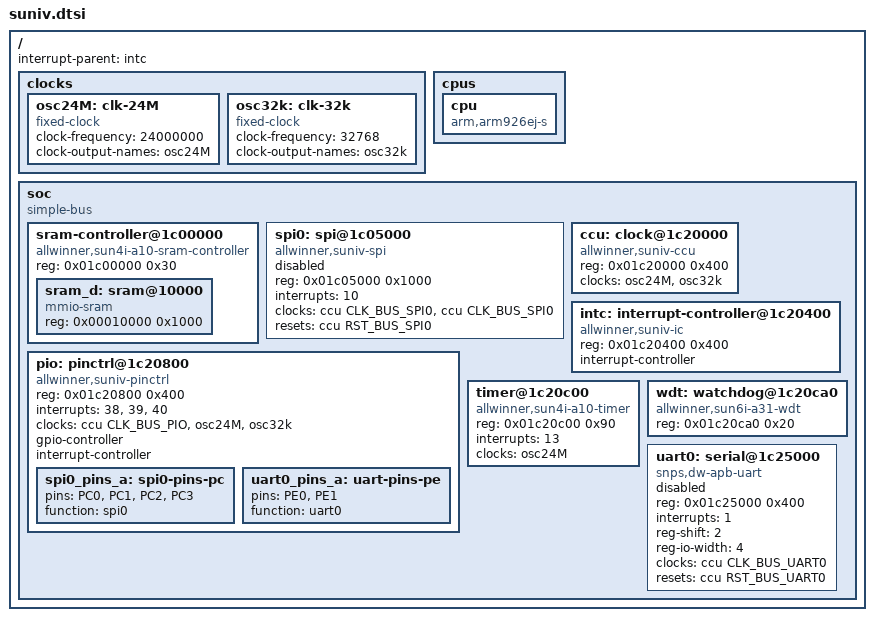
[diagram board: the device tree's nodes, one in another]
// SPDX-License-Identifier: (GPL-2.0+ OR X11)
/*
 * Copyright 2018 Icenowy Zheng <icenowy@aosc.io>
 */

#include <dt-bindings/clock/suniv-ccu.h>
#include <dt-bindings/reset/suniv-ccu.h>

/ {
	#address-cells = <1>;
	#size-cells = <1>;
	interrupt-parent = <&intc>;

	clocks {
		#address-cells = <1>;
		#size-cells = <1>;
		ranges;

		osc24M: clk-24M {
			#clock-cells = <0>;
			compatible = "fixed-clock";
			clock-frequency = <24000000>;
			clock-output-names = "osc24M";
		};

		osc32k: clk-32k {
			#clock-cells = <0>;
			compatible = "fixed-clock";
			clock-frequency = <32768>;
			clock-output-names = "osc32k";
		};
	};

	cpus {
		#address-cells = <0>;
		#size-cells = <0>;

		cpu {
			compatible = "arm,arm926ej-s";
			device_type = "cpu";
		};
	};

	soc {
		compatible = "simple-bus";
		#address-cells = <1>;
		#size-cells = <1>;
		ranges;

		sram-controller@1c00000 {
			compatible = "allwinner,sun4i-a10-sram-controller";
			reg = <0x01c00000 0x30>;
			#address-cells = <1>;
			#size-cells = <1>;
			ranges;

			sram_d: sram@10000 {
				compatible = "mmio-sram";
				reg = <0x00010000 0x1000>;
				#address-cells = <1>;
				#size-cells = <1>;
				ranges = <0 0x00010000 0x1000>;
			};
		};

		spi0: spi@1c05000 {
			compatible = "allwinner,suniv-spi",
				     "allwinner,sun8i-h3-spi";
			reg = <0x01c05000 0x1000>;
			interrupts = <10>;
			clocks = <&ccu CLK_BUS_SPI0>, <&ccu CLK_BUS_SPI0>;
			clock-names = "ahb", "mod";
			resets = <&ccu RST_BUS_SPI0>;
			status = "disabled";
			#address-cells = <1>;
			#size-cells = <0>;
		};

		ccu: clock@1c20000 {
			compatible = "allwinner,suniv-ccu";
			reg = <0x01c20000 0x400>;
			clocks = <&osc24M>, <&osc32k>;
			clock-names = "hosc", "losc";
			#clock-cells = <1>;
			#reset-cells = <1>;
		};

		intc: interrupt-controller@1c20400 {
			compatible = "allwinner,suniv-ic";
			reg = <0x01c20400 0x400>;
			interrupt-controller;
			#interrupt-cells = <1>;
		};

		pio: pinctrl@1c20800 {
			compatible = "allwinner,suniv-pinctrl";
			reg = <0x01c20800 0x400>;
			interrupts = <38>, <39>, <40>;
			clocks = <&ccu CLK_BUS_PIO>, <&osc24M>, <&osc32k>;
			clock-names = "apb", "hosc", "losc";
			gpio-controller;
			interrupt-controller;
			#interrupt-cells = <3>;
			#gpio-cells = <3>;

			spi0_pins_a: spi0-pins-pc {
				pins = "PC0", "PC1", "PC2", "PC3";
				function = "spi0";
			};

			uart0_pins_a: uart-pins-pe {
				pins = "PE0", "PE1";
				function = "uart0";
			};
		};

		timer@1c20c00 {
			compatible = "allwinner,sun4i-a10-timer";
			reg = <0x01c20c00 0x90>;
			interrupts = <13>;
			clocks = <&osc24M>;
		};

		wdt: watchdog@1c20ca0 {
			compatible = "allwinner,sun6i-a31-wdt";
			reg = <0x01c20ca0 0x20>;
		};

		uart0: serial@1c25000 {
			compatible = "snps,dw-apb-uart";
			reg = <0x01c25000 0x400>;
			interrupts = <1>;
			reg-shift = <2>;
			reg-io-width = <4>;
			clocks = <&ccu CLK_BUS_UART0>;
			resets = <&ccu RST_BUS_UART0>;
			status = "disabled";
		};
	};
};
